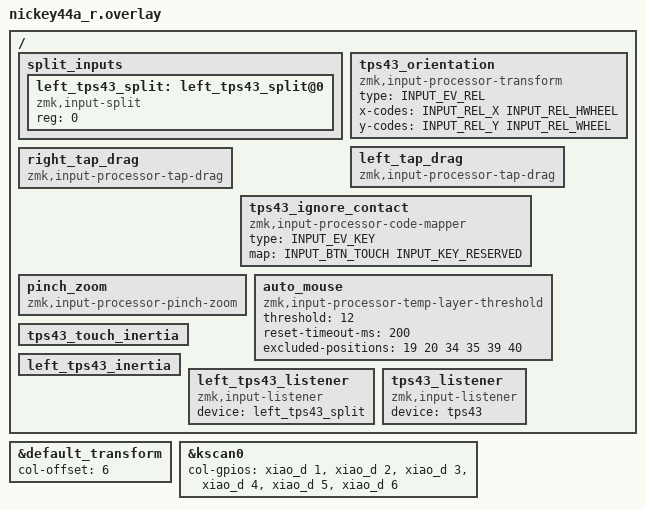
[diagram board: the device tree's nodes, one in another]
#include "nickey44a.dtsi"
#include <input/processors.dtsi>
#include <zephyr/dt-bindings/pinctrl/nrf-pinctrl.h>
#include <dt-bindings/zmk/input_transform.h>
#include <dt-bindings/zmk/keys.h>
#include <zephyr/dt-bindings/input/input-event-codes.h>

#include "tps43.dtsi"
#include "../../../config/nickey_layers.h"

/ {
    split_inputs {
        #address-cells = <1>;
        #size-cells = <0>;

        left_tps43_split: left_tps43_split@0 {
            compatible = "zmk,input-split";
            reg = <0>;
        };
    };

    tps43_orientation: tps43_orientation {
        compatible = "zmk,input-processor-transform";
        #input-processor-cells = <1>;
        type = <INPUT_EV_REL>;
        x-codes = <INPUT_REL_X INPUT_REL_HWHEEL>;
        y-codes = <INPUT_REL_Y INPUT_REL_WHEEL>;
    };

    left_tap_drag: left_tap_drag {
        compatible = "zmk,input-processor-tap-drag";
        #input-processor-cells = <2>;
    };

    right_tap_drag: right_tap_drag {
        compatible = "zmk,input-processor-tap-drag";
        #input-processor-cells = <2>;
    };

    /* Tap-drag and inertia observe contact before the mouse listener ignores it. */
    tps43_ignore_contact: tps43_ignore_contact {
        compatible = "zmk,input-processor-code-mapper";
        #input-processor-cells = <0>;
        type = <INPUT_EV_KEY>;
        map = <INPUT_BTN_TOUCH INPUT_KEY_RESERVED>;
    };

    pinch_zoom: pinch_zoom {
        compatible = "zmk,input-processor-pinch-zoom";
        #input-processor-cells = <2>;
    };

    auto_mouse: auto_mouse {
        compatible = "zmk,input-processor-temp-layer-threshold";
        #input-processor-cells = <2>;
        threshold = <12>;
        reset-timeout-ms = <200>;
        excluded-positions = <19 20 34 35 39 40>; // J K , . Delete Space
    };

    /* Runtime filters have per-device motion history. Keep the two pads independent. */
#define PAD_FILTER(node, id_string, x_code, y_code)     \
    node: node {                                        \
        compatible = "zmk,input-processor-runtime";     \
        #input-processor-cells = <0>;                   \
        processor-label = id_string;                    \
        type = <INPUT_EV_REL>;                          \
        x-codes = <x_code>;                             \
        y-codes = <y_code>;                             \
        track-remainders;                               \
    };

    PAD_FILTER(left_mouse, "lmouse", INPUT_REL_X, INPUT_REL_Y)
    PAD_FILTER(left_scroll, "lscroll", INPUT_REL_HWHEEL, INPUT_REL_WHEEL)
    PAD_FILTER(right_mouse, "rmouse", INPUT_REL_X, INPUT_REL_Y)
    PAD_FILTER(right_scroll, "rscroll", INPUT_REL_HWHEEL, INPUT_REL_WHEEL)
#undef PAD_FILTER

    tps43_touch_inertia: tps43_touch_inertia {
#include "tps43-inertia.dtsi"
    };

    left_tps43_inertia: left_tps43_inertia {
#include "tps43-inertia.dtsi"
    };

    left_tps43_listener: left_tps43_listener {
        compatible = "zmk,input-listener";
        device = <&left_tps43_split>;
#define PAD_MOUSE left_mouse
#define PAD_DRAG left_tap_drag
#define PAD_SCROLL left_scroll
#define PAD_INERTIA left_tps43_inertia
#include "tps43-listener.dtsi"
#undef PAD_INERTIA
#undef PAD_MOUSE
#undef PAD_DRAG
#undef PAD_SCROLL
    };

    tps43_listener: tps43_listener {
        compatible = "zmk,input-listener";
        device = <&tps43>;
#define PAD_MOUSE right_mouse
#define PAD_DRAG right_tap_drag
#define PAD_SCROLL right_scroll
#define PAD_INERTIA tps43_touch_inertia
#include "tps43-listener.dtsi"
#undef PAD_INERTIA
#undef PAD_MOUSE
#undef PAD_DRAG
#undef PAD_SCROLL
    };
};

&default_transform {
    col-offset = <6>;
};

&kscan0 {
        col-gpios
            = <&xiao_d 1 GPIO_ACTIVE_HIGH>
            , <&xiao_d 2 GPIO_ACTIVE_HIGH>
            , <&xiao_d 3 GPIO_ACTIVE_HIGH>
            , <&xiao_d 4 GPIO_ACTIVE_HIGH>
            , <&xiao_d 5 GPIO_ACTIVE_HIGH>
            , <&xiao_d 6 GPIO_ACTIVE_HIGH>
            ;
};
